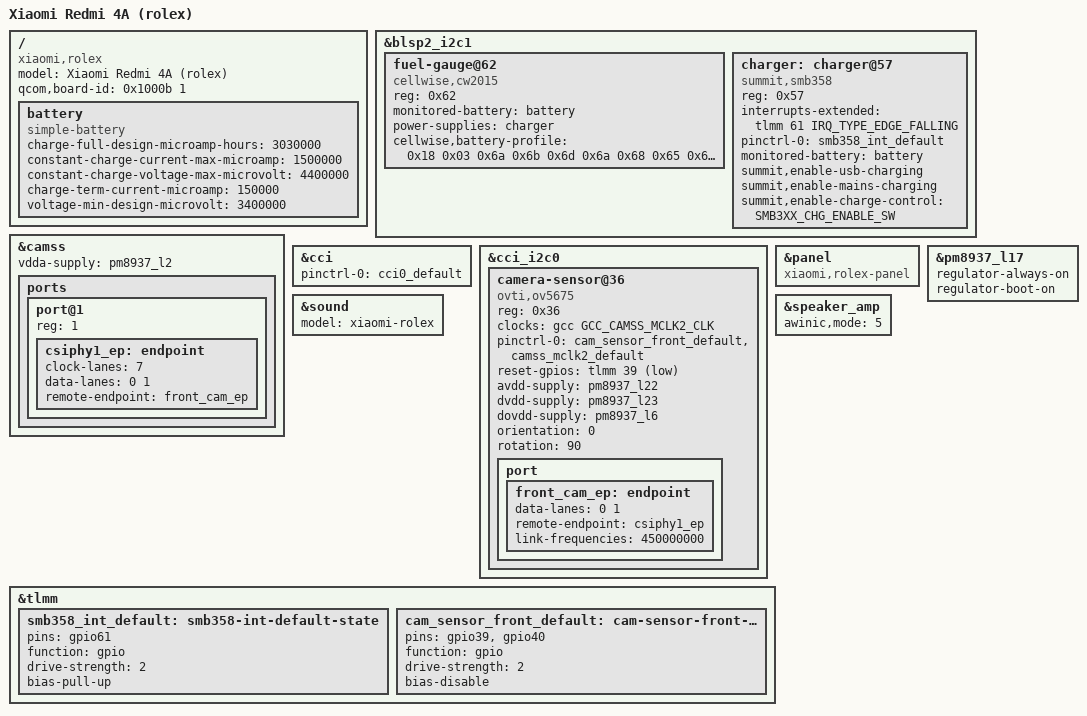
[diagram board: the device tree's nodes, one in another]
// SPDX-License-Identifier: GPL-2.0-only
/*
 * Copyright (c) 2026, Barnabas Czeman
 */

/dts-v1/;

#include <dt-bindings/power/summit,smb347-charger.h>

#include "msm8917-xiaomi-wingtech.dtsi"

/ {
	model = "Xiaomi Redmi 4A (rolex)";
	compatible = "xiaomi,rolex", "qcom,msm8917";

	qcom,board-id = <0x1000b 1>;

	battery: battery {
		compatible = "simple-battery";
		charge-full-design-microamp-hours = <3030000>;
		constant-charge-current-max-microamp = <1500000>;
		constant-charge-voltage-max-microvolt = <4400000>;
		charge-term-current-microamp = <150000>;
		voltage-min-design-microvolt = <3400000>;
	};
};

&blsp2_i2c1 {
	status = "okay";

	fuel-gauge@62 {
		compatible = "cellwise,cw2015";
		reg = <0x62>;
		monitored-battery = <&battery>;
		power-supplies = <&charger>;

		/* wingtech-xingwangda-4v4-3030mah, downstream default profile */
		cellwise,battery-profile = /bits/ 8 <
			0x18 0x03 0x6a 0x6b 0x6d 0x6a 0x68 0x65
			0x60 0x63 0x60 0x54 0x5d 0x59 0x48 0x40
			0x38 0x31 0x27 0x24 0x28 0x31 0x43 0x4d
			0x28 0x49 0x0b 0x85 0x1c 0x37 0x57 0x6e
			0x79 0x7a 0x7a 0x7a 0x3d 0x1a 0x62 0x3f
			0x0a 0x44 0x34 0x55 0x82 0x97 0x9b 0x13
			0x41 0x81 0x94 0xc2 0x74 0x9c 0xbc 0xcb
			0x2f 0x7d 0x72 0xa5 0xb5 0xc1 0x95 0x61
		>;
	};

	charger: charger@57 {
		compatible = "summit,smb358";
		reg = <0x57>;
		interrupts-extended = <&tlmm 61 IRQ_TYPE_EDGE_FALLING>;
		pinctrl-0 = <&smb358_int_default>;
		pinctrl-names = "default";
		monitored-battery = <&battery>;

		summit,enable-usb-charging;
		summit,enable-mains-charging;
		summit,enable-charge-control = <SMB3XX_CHG_ENABLE_SW>;
	};
};

&camss {
	vdda-supply = <&pm8937_l2>;
	status = "okay";

	ports {
		port@1 {
			reg = <1>;

			csiphy1_ep: endpoint {
				clock-lanes = <7>;
				data-lanes = <0 1>;
				remote-endpoint = <&front_cam_ep>;
			};
		};
	};
};

&cci {
	pinctrl-0 = <&cci0_default>;
	pinctrl-names = "default";

	status = "okay";
};

&cci_i2c0 {
	camera-sensor@36 {
		compatible = "ovti,ov5675";

		reg = <0x36>;

		clocks = <&gcc GCC_CAMSS_MCLK2_CLK>;

		pinctrl-0 = <&cam_sensor_front_default>, <&camss_mclk2_default>;
		pinctrl-names = "default";

		reset-gpios = <&tlmm 39 GPIO_ACTIVE_LOW>;

		avdd-supply= <&pm8937_l22>;
		dvdd-supply = <&pm8937_l23>;
		dovdd-supply = <&pm8937_l6>;
		orientation = <0>;
		rotation = <90>;

		port {
			front_cam_ep: endpoint {
				data-lanes = <0 1>;
				remote-endpoint = <&csiphy1_ep>;
				link-frequencies = /bits/ 64 <450000000>;
			};
		};
	};
};

&panel {
	compatible = "xiaomi,rolex-panel";
};

/* Gauge supply, downstream cw2015 vdd-supply */
&pm8937_l17 {
	regulator-always-on;
	regulator-boot-on;
};

&sound {
	model = "xiaomi-rolex";
};

&speaker_amp {
	awinic,mode = <5>;

	status = "okay";
};

&tlmm {
	smb358_int_default: smb358-int-default-state {
		pins = "gpio61";
		function = "gpio";
		drive-strength = <2>;
		bias-pull-up;
	};

	cam_sensor_front_default: cam-sensor-front-default-state {
		pins = "gpio39", "gpio40";
		function = "gpio";
		drive-strength = <2>;
		bias-disable;
	};
};
